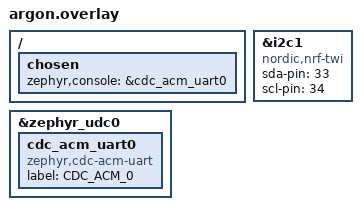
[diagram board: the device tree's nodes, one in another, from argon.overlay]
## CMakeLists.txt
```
# SPDX-License-Identifier: Apache-2.0


set(CONF_FILE prj.conf)
#set(BOARD particle_argon)
set(DTC_OVERLAY_FILE argon.overlay)
cmake_minimum_required(VERSION 3.20.0)
find_package(Zephyr REQUIRED HINTS $ENV{ZEPHYR_BASE})
project(kratos_red)

include_directories(./inc
                    ../../particle_argon/lib)
target_sources(app PRIVATE 
    src/main.c 
    inc/MAX30102.c 
    inc/algorithm.c 
    inc/heart_rate.c 
    src/bpm_spo2.c 
    src/argon_ble.c
    ../../particle_argon/lib/argon_i2c.c)

zephyr_library_include_directories(${ZEPHYR_BASE}/samples/bluetooth)
```

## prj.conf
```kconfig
CONFIG_GPIO=y

#RTT
CONFIG_USB_DEVICE_STACK=y
CONFIG_USB_DEVICE_PRODUCT="Pog0"

CONFIG_SERIAL=y
CONFIG_CONSOLE=y
CONFIG_UART_CONSOLE=y
CONFIG_UART_LINE_CTRL=y
CONFIG_CBPRINTF_FP_SUPPORT=y
CONFIG_NEWLIB_LIBC=y

#--------------------------------USB OPTIONS----------------------------------
CONFIG_USB_DEVICE_PRODUCT="Particle Argon - Zephyr"
CONFIG_USB_DEVICE_MANUFACTURER="Ward RC"
CONFIG_USB_DEVICE_VID=0xC553
CONFIG_USB_DEVICE_PID=0x4011

#i2c
CONFIG_I2C=y


CONFIG_BT=y
CONFIG_BT_DEVICE_NAME="Base"
CONFIG_BT_CENTRAL=y
CONFIG_MINIMAL_LIBC=y




#GATT
CONFIG_BT=y
CONFIG_BT_PERIPHERAL=y
CONFIG_BT_DIS=y
CONFIG_BT_DEVICE_APPEARANCE=833
CONFIG_BT_PRIVACY=y
CONFIG_BT_DEVICE_NAME="Slatty52"
CONFIG_BT_DEVICE_NAME_DYNAMIC=y
CONFIG_BT_DEVICE_NAME_MAX=65
CONFIG_BT_GATT_CLIENT=y
CONFIG_BT_CENTRAL=y

#Enable data signing which is used for transferring authenticated data in an unencrypted connection.
CONFIG_BT_SIGNING=y
```

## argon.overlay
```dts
/*
 *
 * Overlay
 *
 *
 */


/ {
	chosen {
		zephyr,console = &cdc_acm_uart0;
	};
};

&zephyr_udc0 {
	cdc_acm_uart0: cdc_acm_uart0 {
		compatible = "zephyr,cdc-acm-uart";
		label = "CDC_ACM_0";
	};
};

&i2c1 {
	compatible = "nordic,nrf-twi";
	status = "okay";
	sda-pin = <33>;
	scl-pin = <34>;
};
```

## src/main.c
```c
#include <zephyr.h>
#include <device.h>
#include "bpm_spo2.h"
#include "argon_ble.h"
#include "argon_i2c.h"

#define BPM_STACK 1024
#define BPM_PRIO 2

#define BLE_CONNECT_STACK_SIZE 2048
#define BLE_CONNECT_PRIORITY -1

#define DATA_COMM_STACK 512
#define DATA_COMM_PRIO 3

#define RR_STACK_SIZE 512
#define RR_PRIO 1


K_THREAD_DEFINE(bpm_spo2, BPM_STACK, bpm_spo2_thread_start, NULL, NULL, NULL, BPM_PRIO, 0, 100);
K_THREAD_DEFINE(ble_entry, BLE_CONNECT_STACK_SIZE, scu_ble_connect_thread_entry, NULL, NULL, NULL, BLE_CONNECT_PRIORITY, 0, 50);
K_THREAD_DEFINE(data_comm_entry, DATA_COMM_STACK, update_data_thread, NULL, NULL, NULL, DATA_COMM_PRIO, 0, 120);

K_THREAD_DEFINE(argonTID, RR_STACK_SIZE,
		amg8833_thread_entry, NULL, NULL, NULL,
		RR_PRIO, 0, 75);


int main() {
    return 1;
}
```

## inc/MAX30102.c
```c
//MAX30102 Pulse detection sensor driver
#include "MAX30102.h"

#define MAX30102_MODE_MULTILED 0x07
#define MAX30102_ADDRESS_WRITE 0xAE
#define MAX30102_MODECONFIG 0x09
#define MAX30102_MODE_MASK 0xF8
#define MAX30102_DIETEMPCONFIG 0x21
#define MAX30102_ADDRESS 0x57
#define MAX30102_PARTID 0xFF
#define MAX30102_PARTID_VALUE 0x15
#define MAX30102_SHUTDOWN_MASK 0x7F
#define MAX30102_SHUTDOWN 0x80
#define MAX30102_WAKEUP 0x00
#define MAX30102_RESET_MASK 0xBF
#define MAX30102_RESET 0x40
#define MAX30102_FIFOCONFIG 0x08
#define MAX30102_SAMPLEAVG_MASK 0b00011111
#define MAX30102_SAMPLEAVG_4 0x40
#define MAX30102_SAMPLEAVG_1 0x00
#define MAX30102_ROLLOVER_MASK 0xEF
#define MAX30102_ROLLOVER_ENABLE 0x10
#define MAX30102_ROLLOVER_DISABLE 0x00
#define MAX30102_MODE_REDIRONLY 0x03
#define MAX30102_PARTICLECONFIG 0x0A
#define MAX30102_ADCRANGE_MASK 0x9F
#define MAX30102_ADCRANGE_4096 0x20
#define MAX30102_ADCRANGE_61384 0x60
#define MAX30102_SAMPLERATE_MASK 0xE3
#define MAX30102_SAMPLERATE_100 0x04
#define MAX30102_SAMPLERATE_400 0x0C
#define MAX30102_PULSEWIDTH_MASK 0xFC
#define MAX30102_PULSEWIDTH_411 0x03

#define MAX30102_LED1_PULSEAMP 0x0C
#define MAX30102_LED2_PULSEAMP 0x0D 
#define MAX30102_LED3_PULSEAMP 0x0E
#define MAX30102_LED_PROX_AMP 0x10
#define MAX30102_MULTILEDCONFIG1 0x11 
#define MAX30102_MULTILEDCONFIG2 0x12

#define MAX30105_SLOT1_MASK 0xF8
#define MAX30105_SLOT2_MASK 0x8F

#define SLOT_RED_LED 0x01 
#define SLOT_IR_LED 0x02

#define MAX30102_FIFOREADPTR 0x06 
#define MAX30102_FIFOWRITEPTR 0x04 
#define MAX30102_FIFOOVERFLOW 0x05
#define MAX30102_FIFODATA 0x07 

#define MAX30102_FIFOWRITEPTR 0x04
#define MAX30102_FIFOREADPTR 0x06

#define MAX30102_INTSTAT1 0x00 
#define MAX30102_INTSTAT2 0x01
#define REG_INTR_ENABLE_1 0x02
#define REG_INTR_ENABLE_2 0x03

#define MAX30102_INT_A_FULL_MASK (uint8_t)~0b100000000
#define MAX30102_INT_A_FULL_ENABLE 0x80

#define STORAGE_SIZE 4
#define I2C_BUFFER_LENGTH 32


uint32_t i2c_cfg = I2C_SPEED_SET(I2C_SPEED_FAST) | I2C_MODE_MASTER;
void bitMask(const struct device* dev_i2c, uint8_t reg, uint8_t mask, uint8_t thing);
uint8_t readPartID(const struct device* dev);

//struct for storing sensor state

typedef struct Record {
    uint32_t red[STORAGE_SIZE];
    uint32_t IR[STORAGE_SIZE];
    uint8_t head;
    uint8_t tail;
} sense_struct;

sense_struct sense;

uint8_t activeLEDS;

// Initialise the Sensor and I2C device
void max30102_init(const struct device* i2c_dev) {



    //configure for master mode
    i2c_configure(i2c_dev, i2c_cfg);

    if (!device_is_ready(i2c_dev)) {
        printk("Could not get I2C device\n");
        return;
    }

    //check the correct device is found
    if (readPartID(i2c_dev) != MAX30102_PARTID_VALUE) {
        printk("Unable to find device\n");
    }
    else {
        printk("Device Found!\n");
    }

}

// Read Part ID
uint8_t readPartID(const struct device* dev) {
    uint8_t partid = 0;
    int ret = i2c_reg_read_byte(dev, MAX30102_ADDRESS, MAX30102_PARTID, &partid);
    if (ret) {
        printk("Unable to read deviceID register\n");
    }
    return partid;
}



/*============== Begin Library Functions ====================*/

void shutdown(const struct device* dev) {
    bitMask(dev, MAX30102_MODECONFIG, MAX30102_SHUTDOWN_MASK, MAX30102_SHUTDOWN);
}

void wakeup(const struct device* dev) {
    bitMask(dev, MAX30102_MODECONFIG, MAX30102_SHUTDOWN_MASK, MAX30102_WAKEUP);
}

void softReset(const struct device* dev) {
    bitMask(dev, MAX30102_MODECONFIG, MAX30102_RESET_MASK, MAX30102_RESET);

    uint32_t start_time = k_uptime_get_32();
    uint8_t response = 1;
    while (k_uptime_get_32() - start_time < 100) {
        i2c_reg_read_byte(dev, MAX30102_ADDRESS, MAX30102_MODECONFIG, &response);
        if ((response & MAX30102_RESET) == 0) {
            break;
        }
        k_sleep(K_MSEC(1));
    }

}

void setFIFOAverage(const struct device* dev, uint8_t numberOfSamples) {
    bitMask(dev, MAX30102_FIFOCONFIG, MAX30102_SAMPLEAVG_MASK, numberOfSamples);

}


void enableFIFORollover(const struct device* dev) {
    bitMask(dev, MAX30102_FIFOCONFIG, MAX30102_ROLLOVER_MASK, MAX30102_ROLLOVER_ENABLE);
}

void setLEDMode(const struct device* dev, uint8_t mode) {
    bitMask(dev, MAX30102_MODECONFIG, MAX30102_MODE_MASK, mode);

}

void setADCRange(const struct device* dev, uint8_t adcRange) {
    bitMask(dev, MAX30102_PARTICLECONFIG, MAX30102_ADCRANGE_MASK, adcRange);

}

void setSampleRate(const struct device* dev, uint8_t sampleRate) {
    bitMask(dev, MAX30102_PARTICLECONFIG, MAX30102_SAMPLERATE_MASK, sampleRate);
}

void setPulseWidth(const struct device* dev, uint8_t pulseWidth) {
    bitMask(dev, MAX30102_PARTICLECONFIG, MAX30102_PULSEWIDTH_MASK, pulseWidth);

}

void setPulseAmplitudeRed(const struct device* dev, uint8_t powerLevel) {
    if (i2c_reg_write_byte(dev, MAX30102_ADDRESS, MAX30102_LED1_PULSEAMP, powerLevel)) {
        printk("Write failed :( \n");
    }
}

void setPulseAmplitudeIR(const struct device* dev, uint8_t powerLevel) {
    if (i2c_reg_write_byte(dev, MAX30102_ADDRESS, MAX30102_LED2_PULSEAMP, powerLevel)) {
        printk("Write failed :( \n");
    }
}

void setPulseAmplitudeGreen(const struct device* dev, uint8_t powerLevel) {
    if (i2c_reg_write_byte(dev, MAX30102_ADDRESS, MAX30102_LED3_PULSEAMP, powerLevel)) {
        printk("Write failed :( \n");
    }
}

void setPulseAmplitudeProximity(const struct device* dev, uint8_t powerLevel) {
    if (i2c_reg_write_byte(dev, MAX30102_ADDRESS, MAX30102_LED_PROX_AMP, powerLevel)) {
        printk("Write failed :( \n");
    }
}

void enableSlot(const struct device* dev, uint8_t slot, uint8_t device) {
    switch (slot) {
    case (1):
        bitMask(dev, MAX30102_MULTILEDCONFIG1, MAX30105_SLOT1_MASK, device);
        break;
    case (2):
        bitMask(dev, MAX30102_MULTILEDCONFIG1, MAX30105_SLOT2_MASK, device << 4);
        break;
    default:
        //should never be here
        break;
    }

}

void configureFIFO(const struct device* dev) {
    int ret = i2c_reg_write_byte(dev, MAX30102_ADDRESS, MAX30102_FIFOCONFIG, 0x0f);
    if (ret) {
        printk("Error configuring FIFO\n");
    }
}

void clearFIFO(const struct device* dev) {
    int ret = i2c_reg_write_byte(dev, MAX30102_ADDRESS, MAX30102_FIFOWRITEPTR, 0);
    ret += i2c_reg_write_byte(dev, MAX30102_ADDRESS, MAX30102_FIFOOVERFLOW, 0);
    ret += i2c_reg_write_byte(dev, MAX30102_ADDRESS, MAX30102_FIFOREADPTR, 0);
    if (ret) {
        printk("Error clearing FIFO r/w pointers (ERR: %i)\n", ret);

    }

}

void setInterrupts(const struct device* dev) {
    int ret = i2c_reg_write_byte(dev, MAX30102_ADDRESS, REG_INTR_ENABLE_1, 0xc0);
    if (ret) {
        printk("Error setting interrupt 1\n");
    }
    ret = i2c_reg_write_byte(dev, MAX30102_ADDRESS, REG_INTR_ENABLE_2, 0x00);
    if (ret) {
        printk("Error setting interrupt 2\n");
    }

}

void enableAFull(const struct device* dev) {
    int ret = i2c_reg_write_byte(dev, MAX30102_ADDRESS, REG_INTR_ENABLE_1, 0x40);
    if (ret) {
        printk("Error setting interrupt 1\n");
    }
}

void setFIFOAlmostFull(const struct device* dev, uint8_t samples) {
    bitMask(dev, MAX30102_FIFOCONFIG, 0xF0, samples);
}

bool maxim_max30102_init(const struct device* dev)
/**
* \brief        Initialize the MAX30102
* \par          Details
*               This function initializes the MAX30102
*
* \param        None
*
* \retval       true on success
*/
{
    if (i2c_reg_write_byte(dev, MAX30102_ADDRESS, REG_INTR_ENABLE_1, 0xc0)) // INTR setting
        return false;
    if (i2c_reg_write_byte(dev, MAX30102_ADDRESS, REG_INTR_ENABLE_2, 0x00))
        return false;
    if (i2c_reg_write_byte(dev, MAX30102_ADDRESS, REG_FIFO_WR_PTR, 0x00))  //FIFO_WR_PTR[4:0]
        return false;
    if (i2c_reg_write_byte(dev, MAX30102_ADDRESS, REG_OVF_COUNTER, 0x00))  //OVF_COUNTER[4:0]
        return false;
    if (i2c_reg_write_byte(dev, MAX30102_ADDRESS, REG_FIFO_RD_PTR, 0x00))  //FIFO_RD_PTR[4:0]
        return false;
    if (i2c_reg_write_byte(dev, MAX30102_ADDRESS, REG_FIFO_CONFIG, 0x0f))  //sample avg = 1, fifo rollover=false, fifo almost full = 17
        return false;
    if (i2c_reg_write_byte(dev, MAX30102_ADDRESS, REG_MODE_CONFIG, 0x03))   //0x02 for Red only, 0x03 for SpO2 mode 0x07 multimode LED
        return false;
    if (i2c_reg_write_byte(dev, MAX30102_ADDRESS, REG_SPO2_CONFIG, 0x27))  // SPO2_ADC range = 4096nA, SPO2 sample rate (100 Hz), LED pulseWidth (400uS)
        return false;

    if (i2c_reg_write_byte(dev, MAX30102_ADDRESS, REG_LED1_PA, 0x24))   //Choose value for ~ 7mA for LED1
        return false;
    if (i2c_reg_write_byte(dev, MAX30102_ADDRESS, REG_LED2_PA, 0x24))   // Choose value for ~ 7mA for LED2
        return false;
    if (i2c_reg_write_byte(dev, MAX30102_ADDRESS, REG_PILOT_PA, 0x7f))   // Choose value for ~ 25mA for Pilot LED
        return false;
    return true;
}


void MAX30102_setup(const struct device* dev) {
    //uint8_t dummyVal;
    //i2c_reg_read_byte(dev, MAX30102_ADDRESS, 0, &dummyVal);
    softReset(dev);
    uint8_t ledBrightness = 36; //Options: 0=Off to 255=50mA
    uint8_t heartRateRedLED = 36;
    //maxim_max30102_init(dev);
    //setFIFOAverage(dev, MAX30102_SAMPLEAVG_1);
    //enableFIFORollover(dev);
    setInterrupts(dev);
    configureFIFO(dev);
    setLEDMode(dev, MAX30102_MODE_REDIRONLY);
    activeLEDS = 2;
    setADCRange(dev, MAX30102_ADCRANGE_4096);
    setSampleRate(dev, MAX30102_SAMPLERATE_100);// < -SPO2
    setPulseWidth(dev, MAX30102_PULSEWIDTH_411);
    setPulseAmplitudeRed(dev, heartRateRedLED);
    setPulseAmplitudeIR(dev, ledBrightness);
    enableSlot(dev, 1, SLOT_RED_LED);
    enableSlot(dev, 2, SLOT_IR_LED);
    clearFIFO(dev);
    enableAFull(dev);
}



uint8_t available() {
    int8_t numberOfSamples = sense.head - sense.tail;
    if (numberOfSamples < 0) {
        numberOfSamples += STORAGE_SIZE;
    }
    return numberOfSamples;
}

uint8_t getReadPointer(const struct device* dev) {
    uint8_t rptr = 0;
    int ret = i2c_reg_read_byte(dev, MAX30102_ADDRESS, MAX30102_FIFOREADPTR, &rptr);
    if (ret) {
        printk("Failed to read device read pointer\n");
    }
    return rptr;
}

uint8_t getWritePointer(const struct device* dev) {
    uint8_t wptr = 0;
    int ret = i2c_reg_read_byte(dev, MAX30102_ADDRESS, MAX30102_FIFOWRITEPTR, &wptr);
    if (ret) {
        printk("Failed to read device write pointer\n");
    }
    return wptr;
}

uint8_t readINT1(const struct device* dev) {
    uint8_t status;
    int ret = i2c_reg_read_byte(dev, MAX30102_ADDRESS, MAX30102_INTSTAT1, &status);
    if (ret) {
        printk("Error reading INT1 Status \n");
    }
    return status;
}

uint8_t readINT2(const struct device* dev) {
    uint8_t status;
    int ret = i2c_reg_read_byte(dev, MAX30102_ADDRESS, MAX30102_INTSTAT2, &status);
    if (ret) {
        printk("Error reading INT1 Status \n");
    }
    return status;
}

bool readFIFO(const struct device* dev) {
    uint32_t redLED = 0;
    uint32_t irLED = 0;
    uint8_t ch_i2c_data[6];
    uint32_t un_temp;
    readINT1(dev);
    readINT2(dev);
    int ret = i2c_burst_read(dev, MAX30102_ADDRESS, MAX30102_FIFODATA, ch_i2c_data, 6);
    if (ret) {
        printk("Unable to read FIFO data (ERR: %i)\n", ret);
    }
    un_temp = (unsigned char)ch_i2c_data[0];
    un_temp <<= 16;
    redLED += un_temp;
    un_temp = (unsigned char)ch_i2c_data[1];
    un_temp <<= 8;
    redLED += un_temp;
    un_temp = (unsigned char)ch_i2c_data[2];
    redLED += un_temp;

    un_temp = (unsigned char)ch_i2c_data[3];
    un_temp <<= 16;
    irLED += un_temp;
    un_temp = (unsigned char)ch_i2c_data[4];
    un_temp <<= 8;
    irLED += un_temp;
    un_temp = (unsigned char)ch_i2c_data[5];
    irLED += un_temp;
    redLED &= 0x03FFFF;  //Mask MSB [23:18]
    irLED &= 0x03FFFF;

    sense.red[sense.head] = redLED;
    sense.IR[sense.head] = irLED;
    return true;
}

bool readFIFOv2(const struct device* dev, uint32_t* pun_red_led, uint32_t* pun_ir_led) {
    uint32_t un_temp;
    unsigned char uch_temp;
    *pun_red_led = 0;
    *pun_ir_led = 0;
    char ach_i2c_data[6];

    //read and clear status register
    readINT1(dev);
    readINT2(dev);

    int ret = i2c_burst_read(dev, MAX30102_ADDRESS, MAX30102_FIFODATA, ach_i2c_data, 6);
    if (ret) {
        printk("Unable to read FIFO data (ERR: %i)\n", ret);
    }
    un_temp = (unsigned char)ach_i2c_data[0];
    un_temp <<= 16;
    *pun_red_led += un_temp;
    un_temp = (unsigned char)ach_i2c_data[1];
    un_temp <<= 8;
    *pun_red_led += un_temp;
    un_temp = (unsigned char)ach_i2c_data[2];
    *pun_red_led += un_temp;

    un_temp = (unsigned char)ach_i2c_data[3];
    un_temp <<= 16;
    *pun_ir_led += un_temp;
    un_temp = (unsigned char)ach_i2c_data[4];
    un_temp <<= 8;
    *pun_ir_led += un_temp;
    un_temp = (unsigned char)ach_i2c_data[5];
    *pun_ir_led += un_temp;
    *pun_red_led &= 0x03FFFF;  //Mask MSB [23:18]
    *pun_ir_led &= 0x03FFFF;  //Mask MSB [23:18]


    return true;
}

void reset(const struct device* dev) {
    int ret = i2c_reg_write_byte(dev, MAX30102_ADDRESS, REG_MODE_CONFIG, 0x40);
}

uint8_t check(const struct device* dev) {
    uint8_t readPointer = getReadPointer(dev);
    uint8_t writePointer = getWritePointer(dev);

    int numberOfSamples = 0;

    if (readPointer != writePointer) {
        numberOfSamples = writePointer - readPointer;
        if (numberOfSamples < 0) numberOfSamples += 32; //Wrap condition
        int bytesLeftToRead = numberOfSamples * activeLEDS * 3;

        while (bytesLeftToRead > 0) {
            int toGet = bytesLeftToRead;
            if (toGet > I2C_BUFFER_LENGTH)
            {
                //If toGet is 32 this is bad because we read 6 bytes (Red+IR * 3 = 6) at a time
                //32 % 6 = 2 left over. We don't want to request 32 bytes, we want to request 30.
                //32 % 9 (Red+IR+GREEN) = 5 left over. We want to request 27.

                toGet = I2C_BUFFER_LENGTH - (I2C_BUFFER_LENGTH % (activeLEDS * 3)); //Trim toGet to be a multiple of the samples we need to read
            }

            bytesLeftToRead -= toGet;
            while (toGet > 0) {
                sense.head++;
                sense.head %= STORAGE_SIZE;
                readFIFO(dev);
                toGet -= activeLEDS * 3;
            }
        }



    }
    return 1;
}



bool safeCheck(const struct device* dev, uint8_t timeToCheck) {
    uint32_t markTime = k_uptime_get_32();

    while (1) {
        if ((k_uptime_get_32() - markTime) > timeToCheck) return false;
        if (check(dev) == true) {
            return true;

        }
        k_sleep(K_MSEC(1));
    }
}

uint32_t getIRVal(const struct device* dev) {
    if (safeCheck(dev, 250)) {
        return (sense.IR[sense.head]);
    }
    else {
        return 0;
    }
}

uint32_t getRedVal(const struct device* dev) {
    if (safeCheck(dev, 250)) {
        return (sense.red[sense.head]);
    }
    else {
        return 0;
    }
}



void nextSample() {
    if (available()) { //Only advance the tail if new data is available{
        sense.tail++;
        sense.tail %= STORAGE_SIZE; //Wrap condition
    }
}


/*============== Begin Data fetch functions ==================*/



void bitMask(const struct device* dev_i2c, uint8_t reg, uint8_t mask, uint8_t thing) {
    // Grab current register context
    uint8_t originalContents = 0;
    int ret = i2c_reg_read_byte(dev_i2c, MAX30102_ADDRESS, reg, &originalContents);

    if (ret) {
        printk("Unable to get og contents (err %i), ID: (%x)\n", ret, mask);

    }
    // Zero-out the portions of the register we're interested in
    originalContents = originalContents & mask;

    // Change contents
    ret = i2c_reg_write_byte(dev_i2c, MAX30102_ADDRESS, reg, originalContents | thing);
    if (ret) {
        printk("Unable to write (err %i)\n", ret);
    }
}
```

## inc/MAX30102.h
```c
//MAX30102 Pulse detection header files
#ifndef MAX30102_H
#define MAX30102_H
#include <zephyr.h>
#include <device.h>
#include <devicetree.h>
#include <drivers/gpio.h>
#include <usb/usb_device.h>
#include <zephyr/types.h>
#include <drivers/i2c.h>


#define REG_INTR_ENABLE_1 0x02
#define REG_INTR_ENABLE_2 0x03
#define REG_FIFO_WR_PTR 0x04
#define REG_OVF_COUNTER 0x05
#define REG_FIFO_RD_PTR 0x06
#define REG_FIFO_DATA 0x07
#define REG_FIFO_CONFIG 0x08
#define REG_MODE_CONFIG 0x09
#define REG_SPO2_CONFIG 0x0A
#define REG_LED1_PA 0x0C
#define REG_LED2_PA 0x0D
#define REG_PILOT_PA 0x10
#define REG_MULTI_LED_CTRL1 0x11
#define REG_MULTI_LED_CTRL2 0x12
#define REG_TEMP_INTR 0x1F
#define REG_TEMP_FRAC 0x20
#define REG_TEMP_CONFIG 0x21
#define REG_PROX_INT_THRESH 0x30
#define REG_REV_ID 0xFE
#define REG_PART_ID 0xFF
void max30102_init();
void MAX30102_setup(const struct device* dev);
bool readFIFO(const struct device* dev);
uint32_t getIRVal(const struct device* dev);
uint32_t getRedVal(const struct device* dev);
uint8_t available();
void nextSample();
uint8_t check(const struct device* dev);
bool readFIFOv2(const struct device* dev, uint32_t* pun_red_led, uint32_t* pun_ir_led);
void reset(const struct device* dev);

#endif
```

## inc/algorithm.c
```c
/** \file algorithm.c ******************************************************
*
* Project: MAXREFDES117#
* Filename: algorithm.cpp
* Description: This module calculates the heart rate/SpO2 level
*
*
* --------------------------------------------------------------------
*
* This code follows the following naming conventions:
*
* char              ch_pmod_value
* char (array)      s_pmod_s_string[16]
* float             f_pmod_value
* int32_t           n_pmod_value
* int32_t (array)   an_pmod_value[16]
* int16_t           w_pmod_value
* int16_t (array)   aw_pmod_value[16]
* uint16_t          uw_pmod_value
* uint16_t (array)  auw_pmod_value[16]
* uint8_t           uch_pmod_value
* uint8_t (array)   auch_pmod_buffer[16]
* uint32_t          un_pmod_value
* int32_t *         pn_pmod_value
*
* ------------------------------------------------------------------------- */
/*******************************************************************************
* Copyright (C) 2016 Maxim Integrated Products, Inc., All Rights Reserved.
*
* Permission is hereby granted, free of charge, to any person obtaining a
* copy of this software and associated documentation files (the "Software"),
* to deal in the Software without restriction, including without limitation
* the rights to use, copy, modify, merge, publish, distribute, sublicense,
* and/or sell copies of the Software, and to permit persons to whom the
* Software is furnished to do so, subject to the following conditions:
*
* The above copyright notice and this permission notice shall be included
* in all copies or substantial portions of the Software.
*
* THE SOFTWARE IS PROVIDED "AS IS", WITHOUT WARRANTY OF ANY KIND, EXPRESS
* OR IMPLIED, INCLUDING BUT NOT LIMITED TO THE WARRANTIES OF
* MERCHANTABILITY, FITNESS FOR A PARTICULAR PURPOSE AND NONINFRINGEMENT.
* IN NO EVENT SHALL MAXIM INTEGRATED BE LIABLE FOR ANY CLAIM, DAMAGES
* OR OTHER LIABILITY, WHETHER IN AN ACTION OF CONTRACT, TORT OR OTHERWISE,
* ARISING FROM, OUT OF OR IN CONNECTION WITH THE SOFTWARE OR THE USE OR
* OTHER DEALINGS IN THE SOFTWARE.
*
* Except as contained in this notice, the name of Maxim Integrated
* Products, Inc. shall not be used except as stated in the Maxim Integrated
* Products, Inc. Branding Policy.
*
* The mere transfer of this software does not imply any licenses
* of trade secrets, proprietary technology, copyrights, patents,
* trademarks, maskwork rights, or any other form of intellectual
* property whatsoever. Maxim Integrated Products, Inc. retains all
* ownership rights.
*******************************************************************************
*/
#include "algorithm.h"
//#include "mbed.h"
const uint16_t auw_hamm[31] = { 41,    276,    512,    276,     41 }; //Hamm=  long16(512* hamming(5)');
//uch_spo2_table is computed as  -45.060*ratioAverage* ratioAverage + 30.354 *ratioAverage + 94.845 ;
const uint8_t uch_spo2_table[184] = { 95, 95, 95, 96, 96, 96, 97, 97, 97, 97, 97, 98, 98, 98, 98, 98, 99, 99, 99, 99,
                            99, 99, 99, 99, 100, 100, 100, 100, 100, 100, 100, 100, 100, 100, 100, 100, 100, 100, 100, 100,
                            100, 100, 100, 100, 99, 99, 99, 99, 99, 99, 99, 99, 98, 98, 98, 98, 98, 98, 97, 97,
                            97, 97, 96, 96, 96, 96, 95, 95, 95, 94, 94, 94, 93, 93, 93, 92, 92, 92, 91, 91,
                            90, 90, 89, 89, 89, 88, 88, 87, 87, 86, 86, 85, 85, 84, 84, 83, 82, 82, 81, 81,
                            80, 80, 79, 78, 78, 77, 76, 76, 75, 74, 74, 73, 72, 72, 71, 70, 69, 69, 68, 67,
                            66, 66, 65, 64, 63, 62, 62, 61, 60, 59, 58, 57, 56, 56, 55, 54, 53, 52, 51, 50,
                            49, 48, 47, 46, 45, 44, 43, 42, 41, 40, 39, 38, 37, 36, 35, 34, 33, 31, 30, 29,
                            28, 27, 26, 25, 23, 22, 21, 20, 19, 17, 16, 15, 14, 12, 11, 10, 9, 7, 6, 5,
                            3, 2, 1 };

void maxim_heart_rate_and_oxygen_saturation(uint32_t* pun_ir_buffer, int32_t n_ir_buffer_length, uint32_t* pun_red_buffer, int32_t* pn_spo2, int8_t* pch_spo2_valid,
    int32_t* pn_heart_rate, int8_t* pch_hr_valid)
    /**
    * \brief        Calculate the heart rate and SpO2 level
    * \par          Details
    *               By detecting  peaks of PPG cycle and corresponding AC/DC of red/infra-red signal, the ratio for the SPO2 is computed.
    *               Since this algorithm is aiming for Arm M0/M3. formaula for SPO2 did not achieve the accuracy due to register overflow.
    *               Thus, accurate SPO2 is precalculated and save longo uch_spo2_table[] per each ratio.
    *
    * \param[in]    *pun_ir_buffer           - IR sensor data buffer
    * \param[in]    n_ir_buffer_length      - IR sensor data buffer length
    * \param[in]    *pun_red_buffer          - Red sensor data buffer
    * \param[out]    *pn_spo2                - Calculated SpO2 value
    * \param[out]    *pch_spo2_valid         - 1 if the calculated SpO2 value is valid
    * \param[out]    *pn_heart_rate          - Calculated heart rate value
    * \param[out]    *pch_hr_valid           - 1 if the calculated heart rate value is valid
    *
    * \retval       None
    */
{
    uint32_t un_ir_mean, un_only_once;
    int32_t k, n_i_ratio_count;
    int32_t i, s, m, n_exact_ir_valley_locs_count, n_middle_idx;
    int32_t n_th1, n_npks, n_c_min;
    int32_t an_ir_valley_locs[15];
    int32_t an_exact_ir_valley_locs[15];
    int32_t an_dx_peak_locs[15];
    int32_t n_peak_interval_sum;

    int32_t n_y_ac, n_x_ac;
    int32_t n_spo2_calc;
    int32_t n_y_dc_max, n_x_dc_max;
    int32_t n_y_dc_max_idx, n_x_dc_max_idx;
    int32_t an_ratio[5], n_ratio_average;
    int32_t n_nume, n_denom;
    // remove DC of ir signal    
    un_ir_mean = 0;
    for (k = 0; k < n_ir_buffer_length; k++) un_ir_mean += pun_ir_buffer[k];
    un_ir_mean = un_ir_mean / n_ir_buffer_length;
    for (k = 0; k < n_ir_buffer_length; k++)  an_x[k] = pun_ir_buffer[k] - un_ir_mean;

    // 4 pt Moving Average
    for (k = 0; k < BUFFER_SIZE - MA4_SIZE; k++) {
        n_denom = (an_x[k] + an_x[k + 1] + an_x[k + 2] + an_x[k + 3]);
        an_x[k] = n_denom / (int32_t)4;
    }

    // get difference of smoothed IR signal

    for (k = 0; k < BUFFER_SIZE - MA4_SIZE - 1; k++)
        an_dx[k] = (an_x[k + 1] - an_x[k]);

    // 2-pt Moving Average to an_dx
    for (k = 0; k < BUFFER_SIZE - MA4_SIZE - 2; k++) {
        an_dx[k] = (an_dx[k] + an_dx[k + 1]) / 2;
    }

    // hamming window
    // flip wave form so that we can detect valley with peak detector
    for (i = 0; i < BUFFER_SIZE - HAMMING_SIZE - MA4_SIZE - 2;i++) {
        s = 0;
        for (k = i; k < i + HAMMING_SIZE;k++) {
            s -= an_dx[k] * auw_hamm[k - i];
        }
        an_dx[i] = s / (int32_t)1146; // divide by sum of auw_hamm 
    }


    n_th1 = 0; // threshold calculation
    for (k = 0; k < BUFFER_SIZE - HAMMING_SIZE;k++) {
        n_th1 += ((an_dx[k] > 0) ? an_dx[k] : ((int32_t)0 - an_dx[k]));
    }
    n_th1 = n_th1 / (BUFFER_SIZE - HAMMING_SIZE);
    // peak location is acutally index for sharpest location of raw signal since we flipped the signal         
    maxim_find_peaks(an_dx_peak_locs, &n_npks, an_dx, BUFFER_SIZE - HAMMING_SIZE, n_th1, 8, 5);//peak_height, peak_distance, max_num_peaks 

    n_peak_interval_sum = 0;
    if (n_npks >= 2) {
        for (k = 1; k < n_npks; k++)
            n_peak_interval_sum += (an_dx_peak_locs[k] - an_dx_peak_locs[k - 1]);
        n_peak_interval_sum = n_peak_interval_sum / (n_npks - 1);
        *pn_heart_rate = (int32_t)(6000 / n_peak_interval_sum);// beats per minutes
        *pch_hr_valid = 1;
    }
    else {
        *pn_heart_rate = -999;
        *pch_hr_valid = 0;
    }

    for (k = 0; k < n_npks;k++)
        an_ir_valley_locs[k] = an_dx_peak_locs[k] + HAMMING_SIZE / 2;


    // raw value : RED(=y) and IR(=X)
    // we need to assess DC and AC value of ir and red PPG. 
    for (k = 0; k < n_ir_buffer_length; k++) {
        an_x[k] = pun_ir_buffer[k];
        an_y[k] = pun_red_buffer[k];
    }

    // find precise min near an_ir_valley_locs
    n_exact_ir_valley_locs_count = 0;
    for (k = 0; k < n_npks;k++) {
        un_only_once = 1;
        m = an_ir_valley_locs[k];
        n_c_min = 16777216;//2^24;
        if (m + 5 < BUFFER_SIZE - HAMMING_SIZE && m - 5 > 0) {
            for (i = m - 5;i < m + 5; i++)
                if (an_x[i] < n_c_min) {
                    if (un_only_once > 0) {
                        un_only_once = 0;
                    }
                    n_c_min = an_x[i];
                    an_exact_ir_valley_locs[k] = i;
                }
            if (un_only_once == 0)
                n_exact_ir_valley_locs_count++;
        }
    }
    if (n_exact_ir_valley_locs_count < 2) {
        *pn_spo2 = -999; // do not use SPO2 since signal ratio is out of range
        *pch_spo2_valid = 0;
        return;
    }
    // 4 pt MA
    for (k = 0; k < BUFFER_SIZE - MA4_SIZE; k++) {
        an_x[k] = (an_x[k] + an_x[k + 1] + an_x[k + 2] + an_x[k + 3]) / (int32_t)4;
        an_y[k] = (an_y[k] + an_y[k + 1] + an_y[k + 2] + an_y[k + 3]) / (int32_t)4;
    }

    //using an_exact_ir_valley_locs , find ir-red DC andir-red AC for SPO2 calibration ratio
    //finding AC/DC maximum of raw ir * red between two valley locations
    n_ratio_average = 0;
    n_i_ratio_count = 0;

    for (k = 0; k < 5; k++) an_ratio[k] = 0;
    for (k = 0; k < n_exact_ir_valley_locs_count; k++) {
        if (an_exact_ir_valley_locs[k] > BUFFER_SIZE) {
            *pn_spo2 = -999; // do not use SPO2 since valley loc is out of range
            *pch_spo2_valid = 0;
            return;
        }
    }
    // find max between two valley locations 
    // and use ratio betwen AC compoent of Ir & Red and DC compoent of Ir & Red for SPO2 

    for (k = 0; k < n_exact_ir_valley_locs_count - 1; k++) {
        n_y_dc_max = -16777216;
        n_x_dc_max = -16777216;
        if (an_exact_ir_valley_locs[k + 1] - an_exact_ir_valley_locs[k] > 10) {
            for (i = an_exact_ir_valley_locs[k]; i < an_exact_ir_valley_locs[k + 1]; i++) {
                if (an_x[i] > n_x_dc_max) { n_x_dc_max = an_x[i];n_x_dc_max_idx = i; }
                if (an_y[i] > n_y_dc_max) { n_y_dc_max = an_y[i];n_y_dc_max_idx = i; }
            }
            n_y_ac = (an_y[an_exact_ir_valley_locs[k + 1]] - an_y[an_exact_ir_valley_locs[k]]) * (n_y_dc_max_idx - an_exact_ir_valley_locs[k]); //red
            n_y_ac = an_y[an_exact_ir_valley_locs[k]] + n_y_ac / (an_exact_ir_valley_locs[k + 1] - an_exact_ir_valley_locs[k]);


            n_y_ac = an_y[n_y_dc_max_idx] - n_y_ac;    // subracting linear DC compoenents from raw 
            n_x_ac = (an_x[an_exact_ir_valley_locs[k + 1]] - an_x[an_exact_ir_valley_locs[k]]) * (n_x_dc_max_idx - an_exact_ir_valley_locs[k]); // ir
            n_x_ac = an_x[an_exact_ir_valley_locs[k]] + n_x_ac / (an_exact_ir_valley_locs[k + 1] - an_exact_ir_valley_locs[k]);
            n_x_ac = an_x[n_y_dc_max_idx] - n_x_ac;      // subracting linear DC compoenents from raw 
            n_nume = (n_y_ac * n_x_dc_max) >> 7; //prepare X100 to preserve floating value
            n_denom = (n_x_ac * n_y_dc_max) >> 7;
            if (n_denom > 0 && n_i_ratio_count < 5 && n_nume != 0)
            {
                an_ratio[n_i_ratio_count] = (n_nume * 100) / n_denom; //formular is ( n_y_ac *n_x_dc_max) / ( n_x_ac *n_y_dc_max) ;
                n_i_ratio_count++;
            }
        }
    }

    maxim_sort_ascend(an_ratio, n_i_ratio_count);
    n_middle_idx = n_i_ratio_count / 2;

    if (n_middle_idx > 1)
        n_ratio_average = (an_ratio[n_middle_idx - 1] + an_ratio[n_middle_idx]) / 2; // use median
    else
        n_ratio_average = an_ratio[n_middle_idx];

    if (n_ratio_average > 2 && n_ratio_average < 184) {
        n_spo2_calc = uch_spo2_table[n_ratio_average];
        *pn_spo2 = (int32_t)-45.060 * n_ratio_average * n_ratio_average / 10000 + 30.354 * n_ratio_average / 100 + 94.845;
        *pch_spo2_valid = 1;//  float_SPO2 =  -45.060*n_ratio_average* n_ratio_average/10000 + 30.354 *n_ratio_average/100 + 94.845 ;  // for comparison with table
    }
    else {
        *pn_spo2 = -999; // do not use SPO2 since signal ratio is out of range
        *pch_spo2_valid = 0;
    }
}


void maxim_find_peaks(int32_t* pn_locs, int32_t* pn_npks, int32_t* pn_x, int32_t n_size, int32_t n_min_height, int32_t n_min_distance, int32_t n_max_num)
/**
* \brief        Find peaks
* \par          Details
*               Find at most MAX_NUM peaks above MIN_HEIGHT separated by at least MIN_DISTANCE
*
* \retval       None
*/
{
    maxim_peaks_above_min_height(pn_locs, pn_npks, pn_x, n_size, n_min_height);
    maxim_remove_close_peaks(pn_locs, pn_npks, pn_x, n_min_distance);
    *pn_npks = min(*pn_npks, n_max_num);
}

void maxim_peaks_above_min_height(int32_t* pn_locs, int32_t* pn_npks, int32_t* pn_x, int32_t n_size, int32_t n_min_height)
/**
* \brief        Find peaks above n_min_height
* \par          Details
*               Find all peaks above MIN_HEIGHT
*
* \retval       None
*/
{
    int32_t i = 1, n_width;
    *pn_npks = 0;

    while (i < n_size - 1) {
        if (pn_x[i] > n_min_height && pn_x[i] > pn_x[i - 1]) {            // find left edge of potential peaks
            n_width = 1;
            while (i + n_width < n_size && pn_x[i] == pn_x[i + n_width])    // find flat peaks
                n_width++;
            if (pn_x[i] > pn_x[i + n_width] && (*pn_npks) < 15) {                            // find right edge of peaks
                pn_locs[(*pn_npks)++] = i;
                // for flat peaks, peak location is left edge
                i += n_width + 1;
            }
            else
                i += n_width;
        }
        else
            i++;
    }
}


void maxim_remove_close_peaks(int32_t* pn_locs, int32_t* pn_npks, int32_t* pn_x, int32_t n_min_distance)
/**
* \brief        Remove peaks
* \par          Details
*               Remove peaks separated by less than MIN_DISTANCE
*
* \retval       None
*/
{

    int32_t i, j, n_old_npks, n_dist;

    /* Order peaks from large to small */
    maxim_sort_indices_descend(pn_x, pn_locs, *pn_npks);

    for (i = -1; i < *pn_npks; i++) {
        n_old_npks = *pn_npks;
        *pn_npks = i + 1;
        for (j = i + 1; j < n_old_npks; j++) {
            n_dist = pn_locs[j] - (i == -1 ? -1 : pn_locs[i]); // lag-zero peak of autocorr is at index -1
            if (n_dist > n_min_distance || n_dist < -n_min_distance)
                pn_locs[(*pn_npks)++] = pn_locs[j];
        }
    }

    // Resort indices longo ascending order
    maxim_sort_ascend(pn_locs, *pn_npks);
}

void maxim_sort_ascend(int32_t* pn_x, int32_t n_size)
/**
* \brief        Sort array
* \par          Details
*               Sort array in ascending order (insertion sort algorithm)
*
* \retval       None
*/
{
    int32_t i, j, n_temp;
    for (i = 1; i < n_size; i++) {
        n_temp = pn_x[i];
        for (j = i; j > 0 && n_temp < pn_x[j - 1]; j--)
            pn_x[j] = pn_x[j - 1];
        pn_x[j] = n_temp;
    }
}

void maxim_sort_indices_descend(int32_t* pn_x, int32_t* pn_indx, int32_t n_size)
/**
* \brief        Sort indices
* \par          Details
*               Sort indices according to descending order (insertion sort algorithm)
*
* \retval       None
*/
{
    int32_t i, j, n_temp;
    for (i = 1; i < n_size; i++) {
        n_temp = pn_indx[i];
        for (j = i; j > 0 && pn_x[n_temp] > pn_x[pn_indx[j - 1]]; j--)
            pn_indx[j] = pn_indx[j - 1];
        pn_indx[j] = n_temp;
    }
}
```

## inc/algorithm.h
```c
/** \file algorithm.h ******************************************************
*
* Project: MAXREFDES117#
* Filename: algorithm.h
* Description: This module is the heart rate/SpO2 calculation algorithm header file
*
* Revision History:
*\n 1-18-2016 Rev 01.00 SK Initial release.
*\n
*
* --------------------------------------------------------------------
*
* This code follows the following naming conventions:
*
*\n char              ch_pmod_value
*\n char (array)      s_pmod_s_string[16]
*\n float             f_pmod_value
*\n int32_t           n_pmod_value
*\n int32_t (array)   an_pmod_value[16]
*\n int16_t           w_pmod_value
*\n int16_t (array)   aw_pmod_value[16]
*\n uint16_t          uw_pmod_value
*\n uint16_t (array)  auw_pmod_value[16]
*\n uint8_t           uch_pmod_value
*\n uint8_t (array)   auch_pmod_buffer[16]
*\n uint32_t          un_pmod_value
*\n int32_t *         pn_pmod_value
*
* ------------------------------------------------------------------------- */
/*******************************************************************************
* Copyright (C) 2015 Maxim Integrated Products, Inc., All Rights Reserved.
*
* Permission is hereby granted, free of charge, to any person obtaining a
* copy of this software and associated documentation files (the "Software"),
* to deal in the Software without restriction, including without limitation
* the rights to use, copy, modify, merge, publish, distribute, sublicense,
* and/or sell copies of the Software, and to permit persons to whom the
* Software is furnished to do so, subject to the following conditions:
*
* The above copyright notice and this permission notice shall be included
* in all copies or substantial portions of the Software.
*
* THE SOFTWARE IS PROVIDED "AS IS", WITHOUT WARRANTY OF ANY KIND, EXPRESS
* OR IMPLIED, INCLUDING BUT NOT LIMITED TO THE WARRANTIES OF
* MERCHANTABILITY, FITNESS FOR A PARTICULAR PURPOSE AND NONINFRINGEMENT.
* IN NO EVENT SHALL MAXIM INTEGRATED BE LIABLE FOR ANY CLAIM, DAMAGES
* OR OTHER LIABILITY, WHETHER IN AN ACTION OF CONTRACT, TORT OR OTHERWISE,
* ARISING FROM, OUT OF OR IN CONNECTION WITH THE SOFTWARE OR THE USE OR
* OTHER DEALINGS IN THE SOFTWARE.
*
* Except as contained in this notice, the name of Maxim Integrated
* Products, Inc. shall not be used except as stated in the Maxim Integrated
* Products, Inc. Branding Policy.
*
* The mere transfer of this software does not imply any licenses
* of trade secrets, proprietary technology, copyrights, patents,
* trademarks, maskwork rights, or any other form of intellectual
* property whatsoever. Maxim Integrated Products, Inc. retains all
* ownership rights.
*******************************************************************************
*/
#ifndef ALGORITHM_H_
#define ALGORITHM_H_

//#include "mbed.h"

#include <zephyr.h>
#include <device.h>
#include <zephyr/types.h>
#define true 1
#define false 0
#define FS 100
#define BUFFER_SIZE  (FS* 5) 
#define HR_FIFO_SIZE 7
#define MA4_SIZE  4 // DO NOT CHANGE
#define HAMMING_SIZE  5// DO NOT CHANGE
#define min(x,y) ((x) < (y) ? (x) : (y))

//const uint16_t auw_hamm[31]={ 41,    276,    512,    276,     41 }; //Hamm=  long16(512* hamming(5)');
//uch_spo2_table is computed as - 45.060 * ratioAverage * ratioAverage + 30.354 * ratioAverage + 94.845;
//const uint8_t uch_spo2_table[184]={ 95, 95, 95, 96, 96, 96, 97, 97, 97, 97, 97, 98, 98, 98, 98, 98, 99, 99, 99, 99, 
//                            99, 99, 99, 99, 100, 100, 100, 100, 100, 100, 100, 100, 100, 100, 100, 100, 100, 100, 100, 100, 
//                            100, 100, 100, 100, 99, 99, 99, 99, 99, 99, 99, 99, 98, 98, 98, 98, 98, 98, 97, 97, 
//                            97, 97, 96, 96, 96, 96, 95, 95, 95, 94, 94, 94, 93, 93, 93, 92, 92, 92, 91, 91, 
//                            90, 90, 89, 89, 89, 88, 88, 87, 87, 86, 86, 85, 85, 84, 84, 83, 82, 82, 81, 81, 
//                            80, 80, 79, 78, 78, 77, 76, 76, 75, 74, 74, 73, 72, 72, 71, 70, 69, 69, 68, 67, 
//                            66, 66, 65, 64, 63, 62, 62, 61, 60, 59, 58, 57, 56, 56, 55, 54, 53, 52, 51, 50, 
//                            49, 48, 47, 46, 45, 44, 43, 42, 41, 40, 39, 38, 37, 36, 35, 34, 33, 31, 30, 29, 
//                            28, 27, 26, 25, 23, 22, 21, 20, 19, 17, 16, 15, 14, 12, 11, 10, 9, 7, 6, 5, 
//                            3, 2, 1 } ;
static  int32_t an_dx[BUFFER_SIZE - MA4_SIZE]; // delta
static  int32_t an_x[BUFFER_SIZE]; //ir
static  int32_t an_y[BUFFER_SIZE]; //red


void maxim_heart_rate_and_oxygen_saturation(uint32_t* pun_ir_buffer, int32_t n_ir_buffer_length, uint32_t* pun_red_buffer, int32_t* pn_spo2, int8_t* pch_spo2_valid, int32_t* pn_heart_rate, int8_t* pch_hr_valid);
void maxim_find_peaks(int32_t* pn_locs, int32_t* pn_npks, int32_t* pn_x, int32_t n_size, int32_t n_min_height, int32_t n_min_distance, int32_t n_max_num);
void maxim_peaks_above_min_height(int32_t* pn_locs, int32_t* pn_npks, int32_t* pn_x, int32_t n_size, int32_t n_min_height);
void maxim_remove_close_peaks(int32_t* pn_locs, int32_t* pn_npks, int32_t* pn_x, int32_t n_min_distance);
void maxim_sort_ascend(int32_t* pn_x, int32_t n_size);
void maxim_sort_indices_descend(int32_t* pn_x, int32_t* pn_indx, int32_t n_size);

/* ALGORITHM_H_ */
#endif 
```

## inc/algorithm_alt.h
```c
/** \file algorithm.h ******************************************************
*
* Project: MAXREFDES117#
* Filename: algorithm.h
* Description: This module is the heart rate/SpO2 calculation algorithm header file
*
* Revision History:
*\n 1-18-2016 Rev 01.00 SK Initial release.
*\n
*
* --------------------------------------------------------------------
*
* This code follows the following naming conventions:
*
*\n char              ch_pmod_value
*\n char (array)      s_pmod_s_string[16]
*\n float             f_pmod_value
*\n int32_t           n_pmod_value
*\n int32_t (array)   an_pmod_value[16]
*\n int16_t           w_pmod_value
*\n int16_t (array)   aw_pmod_value[16]
*\n uint16_t          uw_pmod_value
*\n uint16_t (array)  auw_pmod_value[16]
*\n uint8_t           uch_pmod_value
*\n uint8_t (array)   auch_pmod_buffer[16]
*\n uint32_t          un_pmod_value
*\n int32_t *         pn_pmod_value
*
* ------------------------------------------------------------------------- */
/*******************************************************************************
* Copyright (C) 2015 Maxim Integrated Products, Inc., All Rights Reserved.
*
* Permission is hereby granted, free of charge, to any person obtaining a
* copy of this software and associated documentation files (the "Software"),
* to deal in the Software without restriction, including without limitation
* the rights to use, copy, modify, merge, publish, distribute, sublicense,
* and/or sell copies of the Software, and to permit persons to whom the
* Software is furnished to do so, subject to the following conditions:
*
* The above copyright notice and this permission notice shall be included
* in all copies or substantial portions of the Software.
*
* THE SOFTWARE IS PROVIDED "AS IS", WITHOUT WARRANTY OF ANY KIND, EXPRESS
* OR IMPLIED, INCLUDING BUT NOT LIMITED TO THE WARRANTIES OF
* MERCHANTABILITY, FITNESS FOR A PARTICULAR PURPOSE AND NONINFRINGEMENT.
* IN NO EVENT SHALL MAXIM INTEGRATED BE LIABLE FOR ANY CLAIM, DAMAGES
* OR OTHER LIABILITY, WHETHER IN AN ACTION OF CONTRACT, TORT OR OTHERWISE,
* ARISING FROM, OUT OF OR IN CONNECTION WITH THE SOFTWARE OR THE USE OR
* OTHER DEALINGS IN THE SOFTWARE.
*
* Except as contained in this notice, the name of Maxim Integrated
* Products, Inc. shall not be used except as stated in the Maxim Integrated
* Products, Inc. Branding Policy.
*
* The mere transfer of this software does not imply any licenses
* of trade secrets, proprietary technology, copyrights, patents,
* trademarks, maskwork rights, or any other form of intellectual
* property whatsoever. Maxim Integrated Products, Inc. retains all
* ownership rights.
*******************************************************************************
*/
#ifndef SPO2_ALGORITHM_H_
#define SPO2_ALGORITHM_H_


#include <zephyr.h>
#include <device.h>
#include <zephyr/types.h>

#define FreqS 25    //sampling frequency
#define BUFFER_SIZE (FreqS * 4) 
#define MA4_SIZE 4 // DONOT CHANGE
#define min(x,y) ((x) < (y) ? (x) : (y)) //Defined in Arduino.h

//uch_spo2_table is approximated as  -45.060*ratioAverage* ratioAverage + 30.354 *ratioAverage + 94.845 ;


void maxim_heart_rate_and_oxygen_saturation(uint32_t* pun_ir_buffer, int32_t n_ir_buffer_length, uint32_t* pun_red_buffer, int32_t* pn_spo2, int8_t* pch_spo2_valid, int32_t* pn_heart_rate, int8_t* pch_hr_valid);

void maxim_find_peaks(int32_t* pn_locs, int32_t* n_npks, int32_t* pn_x, int32_t n_size, int32_t n_min_height, int32_t n_min_distance, int32_t n_max_num);
void maxim_peaks_above_min_height(int32_t* pn_locs, int32_t* n_npks, int32_t* pn_x, int32_t n_size, int32_t n_min_height);
void maxim_remove_close_peaks(int32_t* pn_locs, int32_t* pn_npks, int32_t* pn_x, int32_t n_min_distance);
void maxim_sort_ascend(int32_t* pn_x, int32_t n_size);
void maxim_sort_indices_descend(int32_t* pn_x, int32_t* pn_indx, int32_t n_size);

#endif /* ALGORITHM_H_ */
```

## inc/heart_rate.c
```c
/*
 Optical Heart Rate Detection (PBA Algorithm)
 By: Nathan Seidle
 SparkFun Electronics
 Date: October 2nd, 2016

 Given a series of IR samples from the MAX30105 we discern when a heart beat is occurring
 Let's have a brief chat about what this code does. We're going to try to detect
 heart-rate optically. This is tricky and prone to give false readings. We really don't
 want to get anyone hurt so use this code only as an example of how to process optical
 data. Build fun stuff with our MAX30105 breakout board but don't use it for actual
 medical diagnosis.
 Excellent background on optical heart rate detection:
 http://www.ti.com/lit/an/slaa655/slaa655.pdf
 Good reading:
 http://www.techforfuture.nl/fjc_documents/mitrabaratchi-measuringheartratewithopticalsensor.pdf
 https://fruct.org/publications/fruct13/files/Lau.pdf
 This is an implementation of Maxim's PBA (Penpheral Beat Amplitude) algorithm. It's been
 converted to work within the Arduino framework.
*/

/* Copyright (C) 2016 Maxim Integrated Products, Inc., All Rights Reserved.
*
* Permission is hereby granted, free of charge, to any person obtaining a
* copy of this software and associated documentation files (the "Software"),
* to deal in the Software without restriction, including without limitation
* the rights to use, copy, modify, merge, publish, distribute, sublicense,
* and/or sell copies of the Software, and to permit persons to whom the
* Software is furnished to do so, subject to the following conditions:
*
* The above copyright notice and this permission notice shall be included
* in all copies or substantial portions of the Software.
*
* THE SOFTWARE IS PROVIDED "AS IS", WITHOUT WARRANTY OF ANY KIND, EXPRESS
* OR IMPLIED, INCLUDING BUT NOT LIMITED TO THE WARRANTIES OF
* MERCHANTABILITY, FITNESS FOR A PARTICULAR PURPOSE AND NONINFRINGEMENT.
* IN NO EVENT SHALL MAXIM INTEGRATED BE LIABLE FOR ANY CLAIM, DAMAGES
* OR OTHER LIABILITY, WHETHER IN AN ACTION OF CONTRACT, TORT OR OTHERWISE,
* ARISING FROM, OUT OF OR IN CONNECTION WITH THE SOFTWARE OR THE USE OR
* OTHER DEALINGS IN THE SOFTWARE.
*
* Except as contained in this notice, the name of Maxim Integrated
* Products, Inc. shall not be used except as stated in the Maxim Integrated
* Products, Inc. Branding Policy.
*
* The mere transfer of this software does not imply any licenses
* of trade secrets, proprietary technology, copyrights, patents,
* trademarks, maskwork rights, or any other form of intellectual
* property whatsoever. Maxim Integrated Products, Inc. retains all
* ownership rights.
*
*/

#include "heart_rate.h"

int16_t IR_AC_Max = 20;
int16_t IR_AC_Min = -20;

int16_t IR_AC_Signal_Current = 0;
int16_t IR_AC_Signal_Previous;
int16_t IR_AC_Signal_min = 0;
int16_t IR_AC_Signal_max = 0;
int16_t IR_Average_Estimated;

int16_t positiveEdge = 0;
int16_t negativeEdge = 0;
int32_t ir_avg_reg = 0;

int16_t cbuf[32];
uint8_t offset = 0;

static const uint16_t FIRCoeffs[12] = { 172, 321, 579, 927, 1360, 1858, 2390, 2916, 3391, 3768, 4012, 4096 };

//  Heart Rate Monitor functions takes a sample value and the sample number
//  Returns true if a beat is detected
//  A running average of four samples is recommended for display on the screen.
bool checkForBeat(int32_t sample)
{
    bool beatDetected = false;

    //  Save current state
    IR_AC_Signal_Previous = IR_AC_Signal_Current;

    //This is good to view for debugging
    //Serial.print("Signal_Current: ");
    //Serial.println(IR_AC_Signal_Current);

    //  Process next data sample
    IR_Average_Estimated = averageDCEstimator(&ir_avg_reg, sample);
    IR_AC_Signal_Current = lowPassFIRFilter(sample - IR_Average_Estimated);

    //  Detect positive zero crossing (rising edge)
    if ((IR_AC_Signal_Previous < 0) & (IR_AC_Signal_Current >= 0))
    {

        IR_AC_Max = IR_AC_Signal_max; //Adjust our AC max and min
        IR_AC_Min = IR_AC_Signal_min;

        positiveEdge = 1;
        negativeEdge = 0;
        IR_AC_Signal_max = 0;

        //if ((IR_AC_Max - IR_AC_Min) > 100 & (IR_AC_Max - IR_AC_Min) < 1000)
        if (((IR_AC_Max - IR_AC_Min) > 20) && ((IR_AC_Max - IR_AC_Min) < 1000))
        {
            //Heart beat!!!
            beatDetected = true;
        }
    }

    //  Detect negative zero crossing (falling edge)
    if ((IR_AC_Signal_Previous > 0) & (IR_AC_Signal_Current <= 0))
    {
        positiveEdge = 0;
        negativeEdge = 1;
        IR_AC_Signal_min = 0;
    }

    //  Find Maximum value in positive cycle
    if (positiveEdge & (IR_AC_Signal_Current > IR_AC_Signal_Previous))
    {
        IR_AC_Signal_max = IR_AC_Signal_Current;
    }

    //  Find Minimum value in negative cycle
    if (negativeEdge & (IR_AC_Signal_Current < IR_AC_Signal_Previous))
    {
        IR_AC_Signal_min = IR_AC_Signal_Current;
    }

    return(beatDetected);
}

//  Average DC Estimator
int16_t averageDCEstimator(int32_t* p, uint16_t x)
{
    *p += ((((long)x << 15) - *p) >> 4);
    return (*p >> 15);
}

//  Low Pass FIR Filter
int16_t lowPassFIRFilter(int16_t din)
{
    cbuf[offset] = din;

    int32_t z = mul16(FIRCoeffs[11], cbuf[(offset - 11) & 0x1F]);

    for (uint8_t i = 0; i < 11; i++)
    {
        z += mul16(FIRCoeffs[i], cbuf[(offset - i) & 0x1F] + cbuf[(offset - 22 + i) & 0x1F]);
    }

    offset++;
    offset %= 32; //Wrap condition

    return(z >> 15);
}

//  Integer multiplier
int32_t mul16(int16_t x, int16_t y)
{
    return((long)x * (long)y);
}
```
